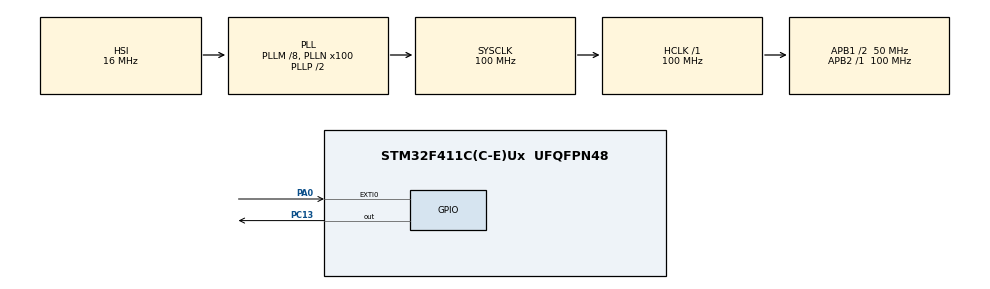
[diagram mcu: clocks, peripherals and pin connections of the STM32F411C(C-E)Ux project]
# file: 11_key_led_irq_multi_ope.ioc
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FREERTOS.Tasks01=defaultTask,24,128,StartDefaultTask,Default,NULL,Dynamic,NULL,NULL
Mcu.Family=STM32F4
Mcu.Name=STM32F411C(C-E)Ux
Mcu.Package=UFQFPN48
NVIC.EXTI0_IRQn=true\:5\:0\:true\:false\:true\:false\:true\:true\:true
NVIC.PriorityGroup=NVIC_PRIORITYGROUP_4
NVIC.TIM1_TRG_COM_TIM11_IRQn=true\:15\:0\:false\:false\:true\:false\:false\:true\:true
NVIC.TimeBase=TIM1_TRG_COM_TIM11_IRQn
NVIC.TimeBaseIP=TIM11
PA0-WKUP.GPIO_ModeDefaultEXTI=GPIO_MODE_IT_RISING_FALLING
PA0-WKUP.GPIO_PuPd=GPIO_PULLUP
PA0-WKUP.Signal=GPXTI0
PA13.Mode=Serial_Wire
PA13.Signal=SYS_JTMS-SWDIO
PA14.Mode=Serial_Wire
PA14.Signal=SYS_JTCK-SWCLK
PC13-ANTI_TAMP.Signal=GPIO_Output
PC14-OSC32_IN.Mode=LSE-External-Oscillator
PC14-OSC32_IN.Signal=RCC_OSC32_IN
PC15-OSC32_OUT.Mode=LSE-External-Oscillator
PC15-OSC32_OUT.Signal=RCC_OSC32_OUT
PH0\ -\ OSC_IN.Mode=HSE-External-Oscillator
PH0\ -\ OSC_IN.Signal=RCC_OSC_IN
PH1\ -\ OSC_OUT.Mode=HSE-External-Oscillator
PH1\ -\ OSC_OUT.Signal=RCC_OSC_OUT
ProjectManager.HeapSize=0x200
ProjectManager.StackSize=0x400
ProjectManager.TargetToolchain=MDK-ARM V5.32
RCC.48MHZClocksFreq_Value=50000000
RCC.AHBFreq_Value=100000000
RCC.APB1CLKDivider=RCC_HCLK_DIV2
RCC.APB1Freq_Value=50000000
RCC.APB1TimFreq_Value=100000000
RCC.APB2Freq_Value=100000000
RCC.APB2TimFreq_Value=100000000
RCC.CortexFreq_Value=100000000
RCC.HCLKFreq_Value=100000000
RCC.HSE_VALUE=25000000
RCC.HSI_VALUE=16000000
RCC.PLLM=8
RCC.PLLN=100
RCC.SYSCLKFreq_VALUE=100000000
RCC.SYSCLKSource=RCC_SYSCLKSOURCE_PLLCLK
RCC.VCOOutputFreq_Value=200000000
VP_FREERTOS_VS_CMSIS_V2.Mode=CMSIS_V2
VP_SYS_VS_tim11.Mode=TIM11
board=custom

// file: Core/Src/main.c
/* USER CODE BEGIN Header */
/**
  ******************************************************************************
  * @file           : main.c
  * @brief          : Main program body
  ******************************************************************************
  * @attention
  *
  * Copyright (c) 2024 STMicroelectronics.
  * All rights reserved.
  *
  * This software is licensed under terms that can be found in the LICENSE file
  * in the root directory of this software component.
  * If no LICENSE file comes with this software, it is provided AS-IS.
  *
  ******************************************************************************
  */
/* USER CODE END Header */
#include "main.h"
#include "cmsis_os.h"
#include "gpio.h"

void SystemClock_Config(void);
void MX_FREERTOS_Init(void);

int main(void)
{

  /* MCU Configuration--------------------------------------------------------*/

  /* Reset of all peripherals, Initializes the Flash interface and the Systick. */
  HAL_Init();

  /* Configure the system clock */
  SystemClock_Config();

  /* Initialize all configured peripherals */
  MX_GPIO_Init();

  /* Init scheduler */
  osKernelInitialize();

  /* Call init function for freertos objects (in cmsis_os2.c) */
  MX_FREERTOS_Init();

  /* Start scheduler */
  osKernelStart();

  /* We should never get here as control is now taken by the scheduler */

  /* Infinite loop */
  while (1)
  {

  }
}

void SystemClock_Config(void)
{
  RCC_OscInitTypeDef RCC_OscInitStruct = {0};
  RCC_ClkInitTypeDef RCC_ClkInitStruct = {0};

  /** Configure the main internal regulator output voltage
  */
  __HAL_RCC_PWR_CLK_ENABLE();
  __HAL_PWR_VOLTAGESCALING_CONFIG(PWR_REGULATOR_VOLTAGE_SCALE1);

  /** Initializes the RCC Oscillators according to the specified parameters
  * in the RCC_OscInitTypeDef structure.
  */
  RCC_OscInitStruct.OscillatorType = RCC_OSCILLATORTYPE_HSI;
  RCC_OscInitStruct.HSIState = RCC_HSI_ON;
  RCC_OscInitStruct.HSICalibrationValue = RCC_HSICALIBRATION_DEFAULT;
  RCC_OscInitStruct.PLL.PLLState = RCC_PLL_ON;
  RCC_OscInitStruct.PLL.PLLSource = RCC_PLLSOURCE_HSI;
  RCC_OscInitStruct.PLL.PLLM = 8;
  RCC_OscInitStruct.PLL.PLLN = 100;
  RCC_OscInitStruct.PLL.PLLP = RCC_PLLP_DIV2;
  RCC_OscInitStruct.PLL.PLLQ = 4;
  if (HAL_RCC_OscConfig(&RCC_OscInitStruct) != HAL_OK)
  {
    Error_Handler();
  }

  /** Initializes the CPU, AHB and APB buses clocks
  */
  RCC_ClkInitStruct.ClockType = RCC_CLOCKTYPE_HCLK|RCC_CLOCKTYPE_SYSCLK
                              |RCC_CLOCKTYPE_PCLK1|RCC_CLOCKTYPE_PCLK2;
  RCC_ClkInitStruct.SYSCLKSource = RCC_SYSCLKSOURCE_PLLCLK;
  RCC_ClkInitStruct.AHBCLKDivider = RCC_SYSCLK_DIV1;
  RCC_ClkInitStruct.APB1CLKDivider = RCC_HCLK_DIV2;
  RCC_ClkInitStruct.APB2CLKDivider = RCC_HCLK_DIV1;

  if (HAL_RCC_ClockConfig(&RCC_ClkInitStruct, FLASH_LATENCY_3) != HAL_OK)
  {
    Error_Handler();
  }
}

void HAL_TIM_PeriodElapsedCallback(TIM_HandleTypeDef *htim)
{
  if (htim->Instance == TIM11) {
    HAL_IncTick();
  }
}

void Error_Handler(void)
{
  __disable_irq();
  while (1)
  {
  }
}

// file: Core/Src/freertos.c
/* USER CODE BEGIN Header */
/**
  ******************************************************************************
  * File Name          : freertos.c
  * Description        : Code for freertos applications
  ******************************************************************************
  * @attention
  *
  * Copyright (c) 2024 STMicroelectronics.
  * All rights reserved.
  *
  * This software is licensed under terms that can be found in the LICENSE file
  * in the root directory of this software component.
  * If no LICENSE file comes with this software, it is provided AS-IS.
  *
  ******************************************************************************
  */
/* USER CODE END Header */

#include "FreeRTOS.h"
#include "task.h"
#include "main.h"
#include "cmsis_os.h"

/* USER CODE BEGIN Includes */
#include "queue.h"
#include "led.h"
/* USER CODE END Includes */

/* USER CODE BEGIN Variables */
QueueHandle_t signal_queue = NULL;
/* USER CODE END Variables */
/* Definitions for defaultTask */
osThreadId_t defaultTaskHandle;
const osThreadAttr_t defaultTask_attributes = {
  .name = "defaultTask",
  .stack_size = 128 * 4,
  .priority = (osPriority_t) osPriorityNormal,
};

void StartDefaultTask(void *argument);

void MX_FREERTOS_Init(void); /* (MISRA C 2004 rule 8.1) */

void MX_FREERTOS_Init(void) {

  /* USER CODE BEGIN RTOS_QUEUES */
    /* add queues, ... */
	signal_queue = xQueueCreate(1, sizeof(uint8_t));
  /* USER CODE END RTOS_QUEUES */

  /* Create the thread(s) */
  /* creation of defaultTask */
  defaultTaskHandle = osThreadNew(StartDefaultTask, NULL, &defaultTask_attributes);

  /* USER CODE BEGIN RTOS_THREADS */
    /* add threads, ... */
    xTaskCreate(led_task, "led_task", 128, NULL, 5, NULL);
  /* USER CODE END RTOS_THREADS */

}

void StartDefaultTask(void *argument)
{
    for(;;)
    {
        osDelay(1);
    }
}
